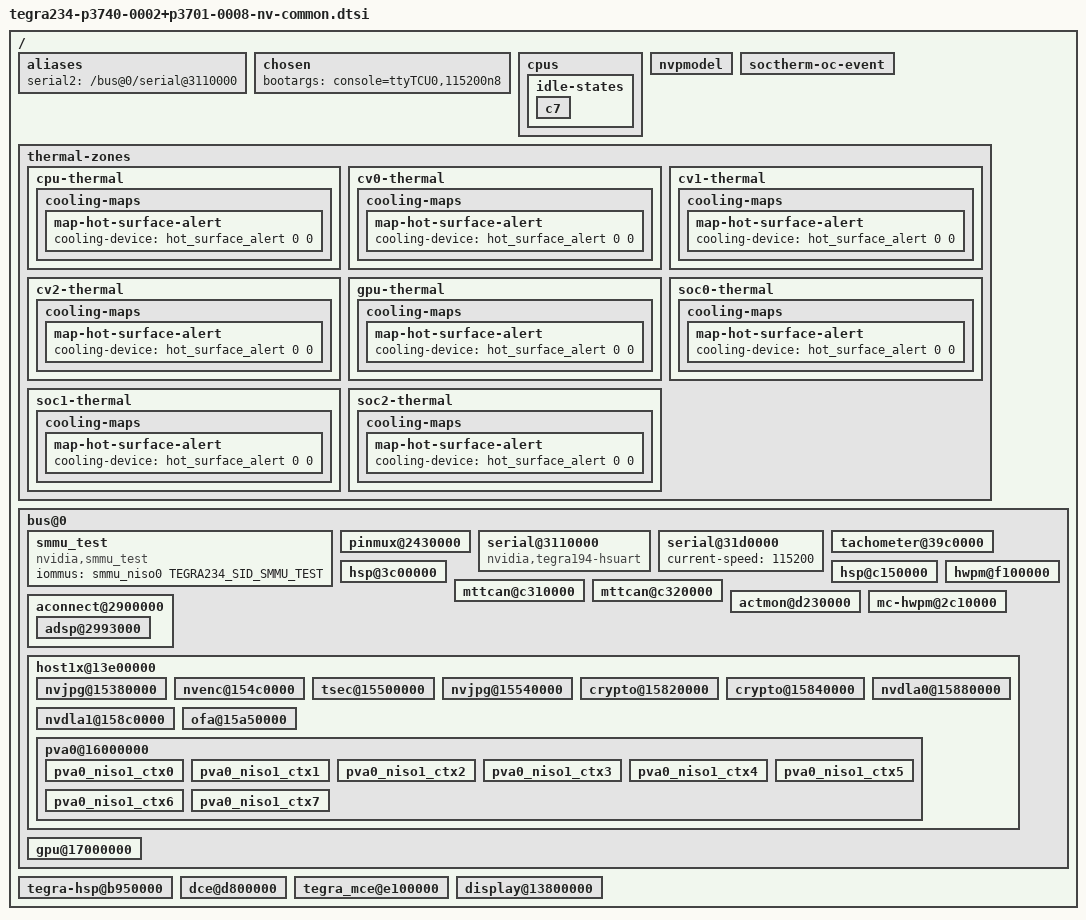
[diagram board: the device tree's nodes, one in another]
// SPDX-License-Identifier: GPL-2.0-only
// SPDX-FileCopyrightText: Copyright (c) 2023-2024, NVIDIA CORPORATION & AFFILIATES.  All rights reserved.

#include "nv-soc/tegra234-overlay.dtsi"
#include "nv-soc/tegra234-soc-camera.dtsi"
#include "tegra234-camera-p3785.dtsi"
#include "tegra234-p3740-0002.dtsi"
#include "tegra234-p3701-0008.dtsi"
#include "tegra234-dcb-p3737-0000-p3701-0000.dtsi"

/ {
	aliases {
		serial2 = "/bus@0/serial@3110000";
	};

	chosen {
		bootargs = "console=ttyTCU0,115200n8";
	};

	cpus {
		idle-states {
			c7 {
				status = "okay";
			};
		};
	};

	nvpmodel {
		status = "okay";
	};

	soctherm-oc-event {
		status = "okay";
	};

	thermal-zones {
		cpu-thermal {
			cooling-maps {
				map-hot-surface-alert {
					cooling-device = <&hot_surface_alert 0 0>;
				};
			};
		};

		cv0-thermal {
			cooling-maps {
				map-hot-surface-alert {
					cooling-device = <&hot_surface_alert 0 0>;
				};
			};
		};

		cv1-thermal {
			cooling-maps {
				map-hot-surface-alert {
					cooling-device = <&hot_surface_alert 0 0>;
				};
			};
		};

		cv2-thermal {
			cooling-maps {
				map-hot-surface-alert {
					cooling-device = <&hot_surface_alert 0 0>;
				};
			};
		};

		gpu-thermal {
			cooling-maps {
				map-hot-surface-alert {
					cooling-device = <&hot_surface_alert 0 0>;
				};
			};
		};

		soc0-thermal {
			cooling-maps {
				map-hot-surface-alert {
					cooling-device = <&hot_surface_alert 0 0>;
				};
			};
		};

		soc1-thermal {
			cooling-maps {
				map-hot-surface-alert {
					cooling-device = <&hot_surface_alert 0 0>;
				};
			};
		};

		soc2-thermal {
			cooling-maps {
				map-hot-surface-alert {
					cooling-device = <&hot_surface_alert 0 0>;
				};
			};
		};
	};

	bus@0 {
		smmu_test {
			compatible = "nvidia,smmu_test";
			iommus = <&smmu_niso0 TEGRA234_SID_SMMU_TEST>;
			status = "okay";
		};

		pinmux@2430000 {
			status = "okay";
		};

		serial@3110000 {
			compatible = "nvidia,tegra194-hsuart";
			reset-names = "serial";
			status = "okay";
		};

		serial@31d0000 {
			current-speed = <115200>;
			status = "okay";                        
		};

		tachometer@39c0000 {
			status = "okay";
		};

		hsp@3c00000 {
			status = "okay";
		};

		hsp@c150000 {
			status = "okay";
		};

		mttcan@c310000 {
			status = "okay";
		};

		mttcan@c320000 {
			status = "okay";
		};

		actmon@d230000 {
			status = "okay";
		};

		hwpm@f100000 {
			status = "okay";
		};

		mc-hwpm@2c10000 {
			status = "okay";
		};

		aconnect@2900000 {
			adsp@2993000 {
				status = "okay";
			};
		};

		host1x@13e00000 {
			nvjpg@15380000 {
				status = "okay";
			};

			nvenc@154c0000 {
				status = "okay";
			};

			tsec@15500000 {
				status = "okay";
			};

			nvjpg@15540000 {
				status = "okay";
			};

			crypto@15820000 {
				status = "okay";
			};

			crypto@15840000 {
				status = "okay";
			};

			nvdla0@15880000 {
				status = "okay";
			};

			nvdla1@158c0000 {
				status = "okay";
			};

			ofa@15a50000 {
				status = "okay";
			};

			pva0@16000000 {
				status = "okay";

				pva0_niso1_ctx0 {
					status = "okay";
				};

				pva0_niso1_ctx1 {
					status = "okay";
				};

				pva0_niso1_ctx2 {
					status = "okay";
				};

				pva0_niso1_ctx3 {
					status = "okay";
				};

				pva0_niso1_ctx4 {
					status = "okay";
				};

				pva0_niso1_ctx5 {
					status = "okay";
				};

				pva0_niso1_ctx6 {
					status = "okay";
				};

				pva0_niso1_ctx7 {
					status = "okay";
				};
			};
		};

		gpu@17000000 {
			status = "okay";
		};
	};

	tegra-hsp@b950000 {
		status = "okay";
	};

	dce@d800000 {
		status = "okay";
	};

	tegra_mce@e100000 {
		status = "okay";
	};

	display@13800000 {
		status = "okay";
	};
};
